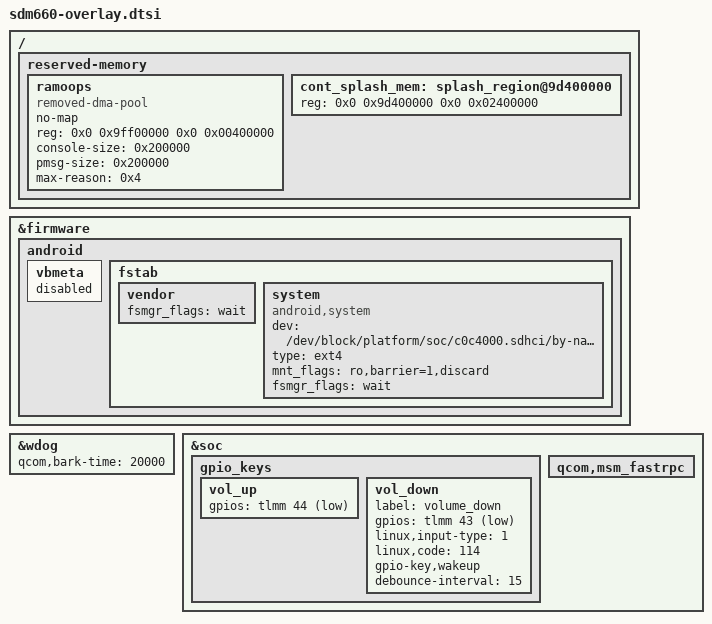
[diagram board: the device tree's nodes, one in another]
/* Copyright (c) 2016-2019, The Linux Foundation. All rights reserved.
 *
 * This program is free software; you can redistribute it and/or modify
 * it under the terms of the GNU General Public License version 2 and
 * only version 2 as published by the Free Software Foundation.
 *
 * This program is distributed in the hope that it will be useful,
 * but WITHOUT ANY WARRANTY; without even the implied warranty of
 * MERCHANTABILITY or FITNESS FOR A PARTICULAR PURPOSE.  See the
 * GNU General Public License for more details.
 */

/ {
	reserved-memory {
		ramoops {
		    status = "ok";
			compatible = "removed-dma-pool", "ramoops";
			no-map;
			reg = <0x0 0x9ff00000 0x0 0x00400000>;
			console-size = <0x200000>;
			pmsg-size = <0x200000>;
			max-reason = <0x4>;
		};

		cont_splash_mem: splash_region@9d400000 {
			reg = <0x0 0x9d400000 0x0 0x02400000>;
		};
	};
};

&firmware {
	android {
		vbmeta {
			status = "disabled";
		};

		fstab {
			vendor {
				fsmgr_flags = "wait";
			};

			system {
				compatible = "android,system";
				dev = "/dev/block/platform/soc/c0c4000.sdhci/by-name/system";
				type = "ext4";
				mnt_flags = "ro,barrier=1,discard";
				fsmgr_flags = "wait";
				status = "ok";
			};
		};
	};
};

&wdog {
	qcom,bark-time = <20000>;
};

&soc {
	gpio_keys {
		/delete-node/ camera_focus;
		/delete-node/ camera_snapshot;

		vol_up {
			gpios = <&tlmm 44 0x1>;
		};

		vol_down {
			label = "volume_down";
			gpios = <&tlmm 43 0x1>;
			linux,input-type = <1>;
			linux,code = <114>;
			gpio-key,wakeup;
			debounce-interval = <15>;
		};
	};

	qcom,msm_fastrpc {
		/delete-property/ qcom,fastrpc-adsp-sensors-pdr;
	};
};
